# G32F031 register map
File version: 1.0
CPU: CM0PLUS r0p1, little endian, no MPU, no FPU, 2 interrupt priority bits
Registers are 32-bit, read-write, reset 0x0 unless marked. A register's access mark holds for its fields unless they carry their own. Offsets are from the block's base; [hi:lo] are bit positions; {n}, {i} and the like mark numbered series.

## RCC — Reset and clock control
Base 0x40020400
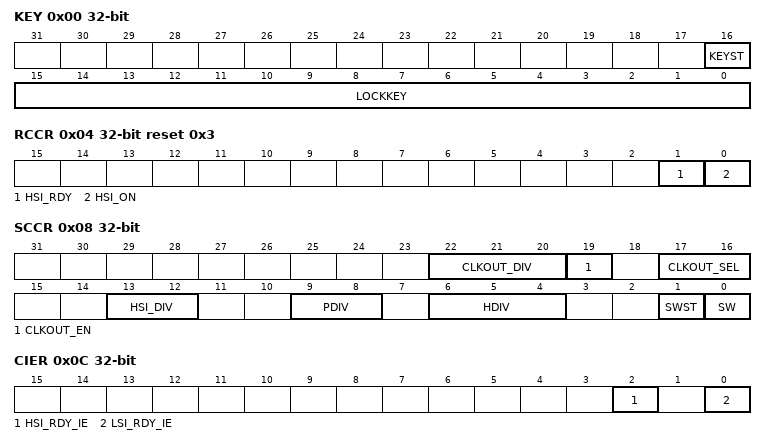
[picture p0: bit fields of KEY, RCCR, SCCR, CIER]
0x00 KEY access per field
  [16] KEYST ro — Register Write Protection Flag
  [15:0] LOCKKEY wo — Password protection configuration for write operations
0x04 RCCR access per field reset 0x3
  [1] HSI_RDY ro — HSI clock stabilization flag
  [0] HSI_ON rw — HSI clock enable
0x08 SCCR access per field
  [22:20] CLKOUT_DIV rw — Clock output division
  [19] CLKOUT_EN rw — Clock output enable
  [17:16] CLKOUT_SEL rw — Clock output select
  [13:12] HSI_DIV rw — System clock HSI branch division
  [9:8] PDIV rw — APB clock division
  [6:4] HDIV rw — AHB clock division
  [1] SWST ro — System clock select flag
  [0] SW rw — System clock select
0x0C CIER
  [2] HSI_RDY_IE — HSI clock stabilization interrupt enable
  [0] LSI_RDY_IE — LSI clock stabilization interrupt enable
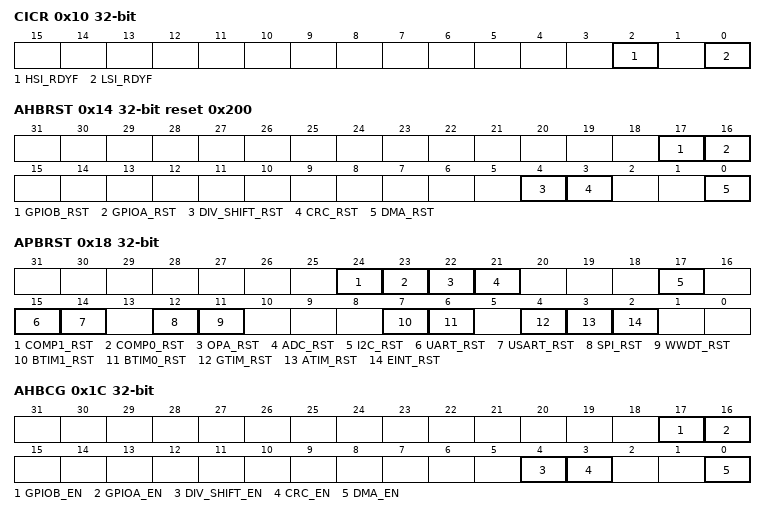
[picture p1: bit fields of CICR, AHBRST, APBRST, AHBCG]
0x10 CICR
  [2] HSI_RDYF — HSI clock stabilization interrupt flag
  [0] LSI_RDYF — LSI clock stabilization interrupt flag
0x14 AHBRST reset 0x200
  [17] GPIOB_RST — GPIOB reset
  [16] GPIOA_RST — GPIOA reset
  [4] DIV_SHIFT_RST — DIV shift reset
  [3] CRC_RST — CRC reset
  [0] DMA_RST — DMA reset
0x18 APBRST
  [24] COMP1_RST — COMP1 reset
  [23] COMP0_RST — COMP0 reset
  [22] OPA_RST — OPA reset
  [21] ADC_RST — ADC reset
  [17] I2C_RST — I2C reset
  [15] UART_RST — UART reset
  [14] USART_RST — USART reset
  [12] SPI_RST — SPI reset
  [11] WWDT_RST — WWDT reset
  [7] BTIM1_RST — BTIM1 reset
  [6] BTIM0_RST — BTIM0 reset
  [4] GTIM_RST — GTIM reset
  [3] ATIM_RST — ATIM resst
  [2] EINT_RST — EINT reset
0x1C AHBCG
  [17] GPIOB_EN — GPIOB clock enable
  [16] GPIOA_EN — GPIOA clock enable
  [4] DIV_SHIFT_EN — DIV SHIFT clock enable
  [3] CRC_EN — CRC clock enable
  [0] DMA_EN — DMA clock enable
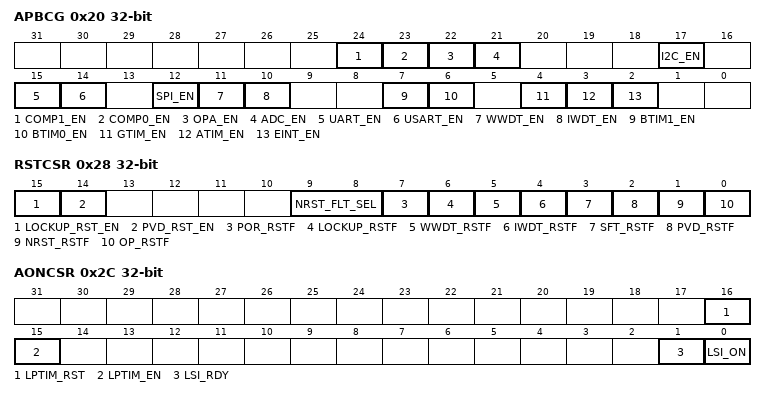
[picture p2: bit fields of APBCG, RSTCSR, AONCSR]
0x20 APBCG
  [24] COMP1_EN — COMP1 enable
  [23] COMP0_EN — COMP0 enable
  [22] OPA_EN — OPA enable
  [21] ADC_EN — ADC enable
  [17] I2C_EN — I2C enable
  [15] UART_EN — UART enable
  [14] USART_EN — USART enable
  [12] SPI_EN — SPI enable
  [11] WWDT_EN — WWDT enable
  [10] IWDT_EN — IWDT enable
  [7] BTIM1_EN — BTIM1 enable
  [6] BTIM0_EN — BTIM0 enable
  [4] GTIM_EN — GTIM enable
  [3] ATIM_EN — ATIM enable
  [2] EINT_EN — EINT enable
0x24 ADCCR
  [1:0] ADC_CLK_DIV — ADC clock division
0x28 RSTCSR
  [15] LOCKUP_RST_EN — LOCKUP system reset enable
  [14] PVD_RST_EN — PVD system reset enable
  [9:8] NRST_FLT_SEL — NRST filter select
  [7] POR_RSTF — POR/PDR reset flag
  [6] LOCKUP_RSTF — LOCKUP system reset flag
  [5] WWDT_RSTF — WWDT system reset flag
  [4] IWDT_RSTF — IWDT system reset flag
  [3] SFT_RSTF — Soft system reset flag
  [2] PVD_RSTF — PVD system reset flag
  [1] NRST_RSTF — NRST reset flag
  [0] OP_RSTF — OB reload system reset flag
0x2C AONCSR access per field
  [16] LPTIM_RST rw — LPTIM reset
  [15] LPTIM_EN rw — LPTIM clock enable
  [1] LSI_RDY ro — LSI clock ready flag
  [0] LSI_ON rw — LSI clock enable

## FLASH — Flash memory controller
Base 0x40020800
0x00 RKEY — /
  [0] RKEY — Status 1: Unlocked. Status 0: Locked
0x04 MKEY — /
  [0] MKEY — Status 1: Unlocked. Status 0: Locked
0x08 NVRBKEY — /
  [0] NVRBKEY — Status 1: Unlocked. Status 0: Locked
0x0C NVRCKEY — /
  [0] NVRCKEY — Status 1: Unlocked. Status 0: Locked
0x10 NVRLKEY — /
  [0] NVRLKEY — Status 1: Unlocked. Status 0: Locked
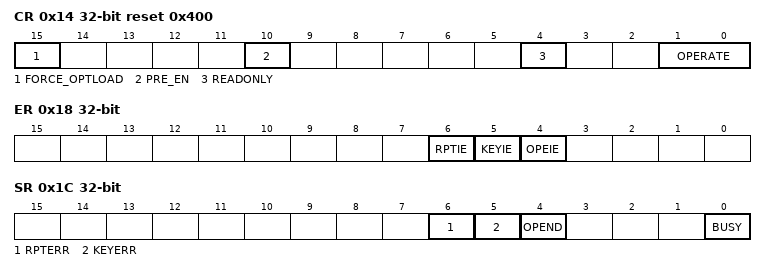
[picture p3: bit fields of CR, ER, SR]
0x14 CR reset 0x400 — /
  [15] FORCE_OPTLOAD — The option byte is forcibly updated. When the data written to the high 16 bits is 0xa5a5 at the same time, the bit can be written as 1. When it is written as 1, the bit forcibly reloads the option byte, which will trigger a system reset. 0: Invalid 1: Valid
  [10] PRE_EN — Pre fetch enable.
  [4] READONLY — Flash ip read-only control, cannot be erased/written.
  [1:0] OPERATE — Flash operation type configuration
0x18 ER — /
  [6] RPTIE — FLASH Read/Write Protection Interrupt Enable
  [5] KEYIE — Flash KEY Error Interrupt Enable
  [4] OPEIE — FLSAH Erase End Interrupt Enable
0x1C SR access per field — /
  [6] RPTERR rw — FLASH read and write protection error interrupt
  [5] KEYERR rw — Flash KEY error interrupt, not unlocking flash erase.
  [4] OPEND rw — FLASH erase finish interrupt
  [0] BUSY ro — FLASH erase BUSY bit
0x20 CR1 reset 0x3 — /
  [1:0] LATENCY — The default value for the delay period on power-up at 64mhz (48mhz) is 2.

## CRC — Cryptographic processor
Base 0x40020C00
0x00 DATA
  [31:0] DATA — As an input register: stores new data for the CRC calculator when writing; As an output register: returns the result of the CRC calculation when reading.
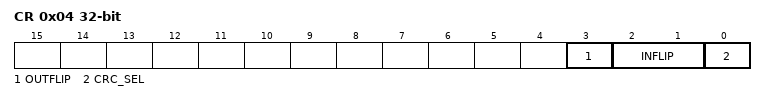
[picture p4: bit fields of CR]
0x04 CR — Control Register
  [3] OUTFLIP — Flip or not flip
  [2:1] INFLIP — Flip the input data in different units: do not flip, flip by byte, flip by half-word, flip by word.
  [0] CRC_SEL — 32-bit, 16-bit CRC selection
0x08 RSTDATA — Initial value data register
  [31:0] RSTDATA — Setting the initial value of CRC.

## DIV
Base 0x40021000
0x00 DVDR — Dividend register
  [31:0] DIVIDEND
0x04 DVSR reset 0x1 — Divisor Register
  [31:0] DIVISOR
0x08 QUOTR wo — Quotient register
  [31:0] QUOTIENT
0x0C RMDR — Remainder register
  [31:0] REMAINDER
0x10 SR — Stauts register
  [0] OVF — Divide by zero overflow status flag
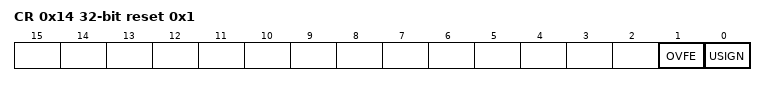
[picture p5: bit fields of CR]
0x14 CR reset 0x1 — Control register
  [1] OVFE — Oerflow interrupt enable
  [0] USIGN — Unsigned enable

## GPIOA — General-purpose I/Os
Base 0x48000000
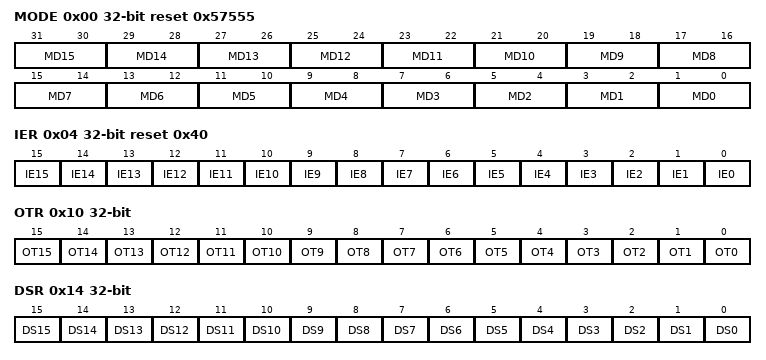
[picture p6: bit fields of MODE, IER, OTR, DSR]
0x00 MODE reset 0x57555
  [2n+1:2n] MD{n} (n=0..15) — /
0x04 IER reset 0x40
  [n] IE{n} (n=0..15) — /
0x0C PUPDR reset 0x1000
  [n+1] PUS{n} (n=0..15) — /
  [n] PUE{n} (n=0..15) — /
0x10 OTR
  [n] OT{n} (n=0..15) — /
0x14 DSR
  [n] DS{n} (n=0..15) — /
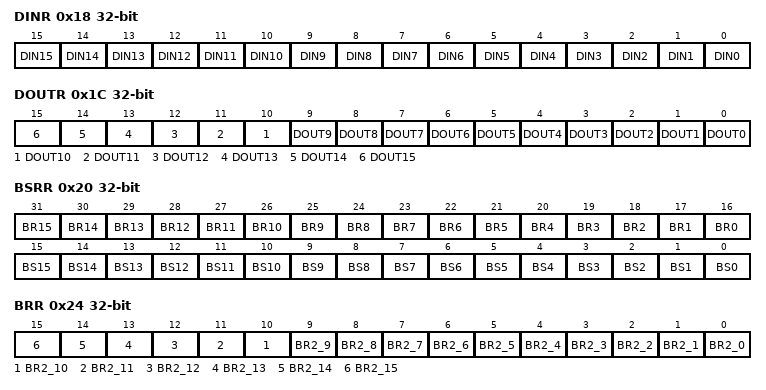
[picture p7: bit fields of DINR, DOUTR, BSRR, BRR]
0x18 DINR
  [n] DIN{n} (n=0..15) — /
0x1C DOUTR
  [n] DOUT{n} (n=0..15) — /
0x20 BSRR
  [n+16] BR{n} (n=0..15) — /
  [n] BS{n} (n=0..15) — /
0x24 BRR
  [n] BR2_{n} (n=0..15) — /
0x28 LCKR
  [31:0] KEY — /
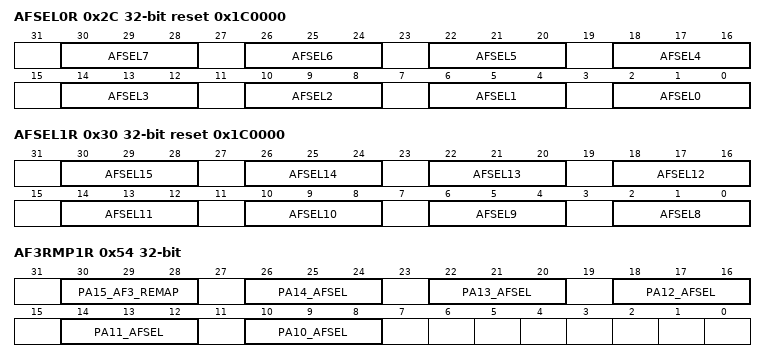
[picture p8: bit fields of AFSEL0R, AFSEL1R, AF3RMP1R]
0x2C AFSEL0R reset 0x1C0000
  [4n+2:4n] AFSEL{n} (n=0..7) — /
0x30 AFSEL1R reset 0x1C0000
  [4n-30:4n-32] AFSEL{n} (n=8..15) — /
0x54 AF3RMP1R
  [30:28] PA15_AF3_REMAP — /
  [4n-30:4n-32] PA{n}_AFSEL (n=10..14) — /

## GPIOB — General-purpose I/Os
Base 0x48000400
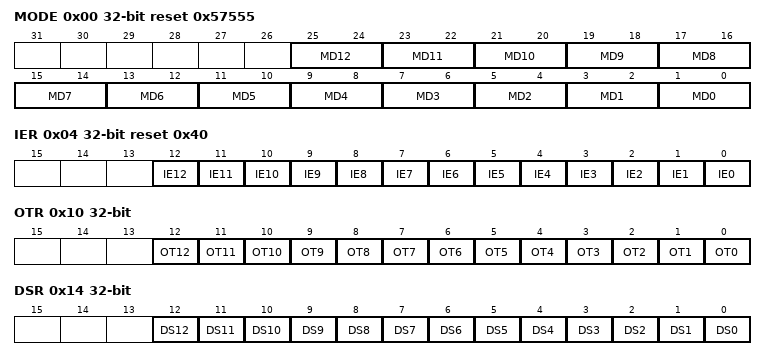
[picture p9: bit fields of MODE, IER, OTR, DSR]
0x00 MODE reset 0x57555
  [2n+1:2n] MD{n} (n=0..12) — /
0x04 IER reset 0x40
  [n] IE{n} (n=0..12) — /
0x0C PUPDR reset 0x1000
  [n+1] PUS{n} (n=0..12) — /
  [n] PUE{n} (n=0..12) — /
0x10 OTR
  [n] OT{n} (n=0..12) — /
0x14 DSR
  [n] DS{n} (n=0..12) — /
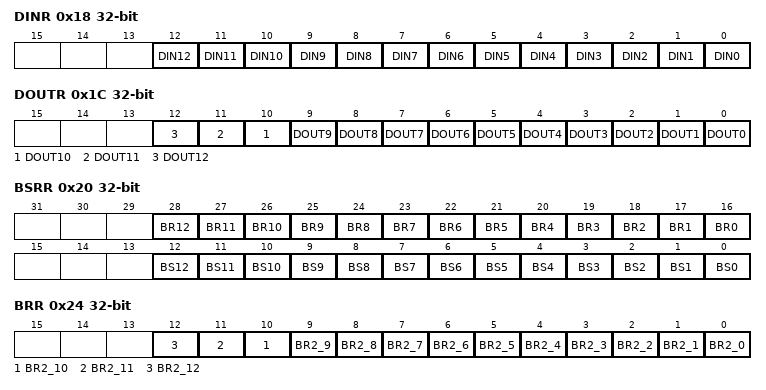
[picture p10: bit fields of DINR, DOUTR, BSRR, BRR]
0x18 DINR
  [n] DIN{n} (n=0..12) — /
0x1C DOUTR
  [n] DOUT{n} (n=0..12) — /
0x20 BSRR
  [n+16] BR{n} (n=0..12) — /
  [n] BS{n} (n=0..12) — /
0x24 BRR
  [n] BR2_{n} (n=0..12) — /
0x28 LCKR
  [31:0] KEY — /
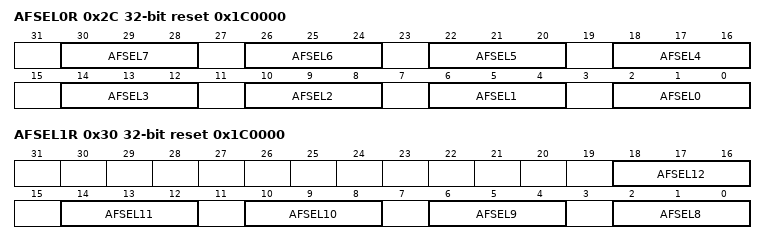
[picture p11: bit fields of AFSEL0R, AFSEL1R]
0x2C AFSEL0R reset 0x1C0000
  [4n+2:4n] AFSEL{n} (n=0..7) — /
0x30 AFSEL1R reset 0x1C0000
  [4n-30:4n-32] AFSEL{n} (n=8..12) — /

## OPA — Window watchdog
Base 0x40005800
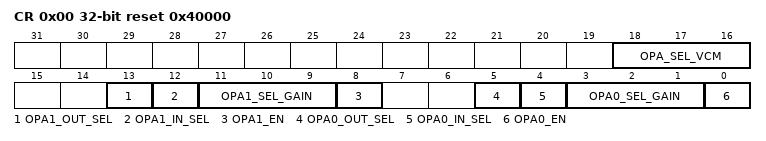
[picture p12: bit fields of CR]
0x00 CR reset 0x40000 — Control register
  [18:16] OPA_SEL_VCM, [13] OPA1_OUT_SEL, [12] OPA1_IN_SEL, [11:9] OPA1_SEL_GAIN, [8] OPA1_EN, [5] OPA0_OUT_SEL, [4] OPA0_IN_SEL, [3:1] OPA0_SEL_GAIN, [0] OPA0_EN
